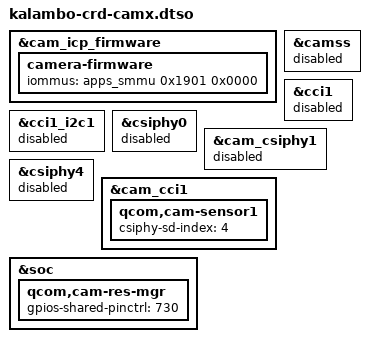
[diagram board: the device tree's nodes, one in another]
// SPDX-License-Identifier: BSD-3-Clause
/*
 * Copyright (c) Qualcomm Technologies, Inc. and/or its subsidiaries.
 */

/dts-v1/;
/plugin/;

#include <dt-bindings/clock/qcom,glymur-camcc.h>
#include <dt-bindings/clock/qcom,glymur-gcc.h>
#include <dt-bindings/gpio/gpio.h>
#include <dt-bindings/interconnect/qcom,glymur-rpmh.h>
#include <dt-bindings/interconnect/qcom,icc.h>
#include <dt-bindings/interrupt-controller/arm-gic.h>
#include <dt-bindings/phy/phy.h>
#include <dt-bindings/pinctrl/qcom,pmic-gpio.h>
#include <dt-bindings/power/qcom-rpmpd.h>

#include "glymur-camera.dtsi"
#include "glymur-camera-sensor.dtsi"

&cam_icp_firmware {
	camera-firmware {
		iommus = <&apps_smmu 0x1901 0x0000>;
	};
};

&camss {
	status = "disabled";
};

&cci1 {
	status = "disabled";
};

&cci1_i2c1 {
	status = "disabled";
};

&csiphy0 {
	status = "disabled";
};

&cam_csiphy1 {
	status = "disabled";
};

&csiphy4 {
	status = "disabled";
};

&cam_cci1 {
	/* cam1-og0va1b shares the combo PHY with cam0 on kalambo. */
	qcom,cam-sensor1 {
		csiphy-sd-index = <4>;
	};
};

&soc {
	qcom,cam-res-mgr {
		gpios-shared-pinctrl = <730>;
	};
};
